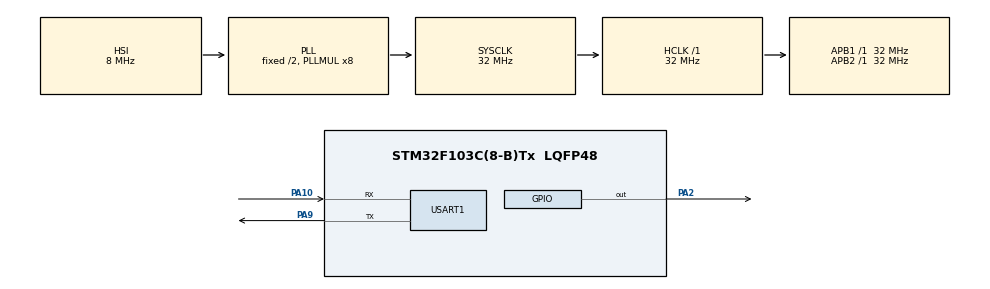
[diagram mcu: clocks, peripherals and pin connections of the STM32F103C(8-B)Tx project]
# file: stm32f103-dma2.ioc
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Dma.Request0=TIM2_UP
Dma.TIM2_UP.0.Direction=DMA_MEMORY_TO_PERIPH
Dma.TIM2_UP.0.Instance=DMA1_Channel2
Dma.TIM2_UP.0.MemDataAlignment=DMA_MDATAALIGN_WORD
Dma.TIM2_UP.0.MemInc=DMA_MINC_ENABLE
Dma.TIM2_UP.0.Mode=DMA_NORMAL
Dma.TIM2_UP.0.PeriphDataAlignment=DMA_PDATAALIGN_WORD
Dma.TIM2_UP.0.PeriphInc=DMA_PINC_DISABLE
Dma.TIM2_UP.0.Priority=DMA_PRIORITY_VERY_HIGH
Mcu.Family=STM32F1
Mcu.Name=STM32F103C(8-B)Tx
Mcu.Package=LQFP48
NVIC.DMA1_Channel2_IRQn=true\:0\:0\:false\:false\:true\:false\:true\:true
NVIC.PriorityGroup=NVIC_PRIORITYGROUP_4
PA10.Mode=Asynchronous
PA10.Signal=USART1_RX
PA2.GPIO_Speed=GPIO_SPEED_FREQ_HIGH
PA2.PinState=GPIO_PIN_SET
PA2.Signal=GPIO_Output
PA9.Mode=Asynchronous
PA9.Signal=USART1_TX
ProjectManager.HeapSize=0x200
ProjectManager.StackSize=0x400
ProjectManager.TargetToolchain=EWARM V8.32
RCC.AHBFreq_Value=32000000
RCC.APB1Freq_Value=32000000
RCC.APB1TimFreq_Value=32000000
RCC.APB2Freq_Value=32000000
RCC.APB2TimFreq_Value=32000000
RCC.HCLKFreq_Value=32000000
RCC.PLLMUL=RCC_PLL_MUL8
RCC.SYSCLKFreq_VALUE=32000000
RCC.SYSCLKSource=RCC_SYSCLKSOURCE_PLLCLK
RCC.USBFreq_Value=32000000
USART1.VirtualMode=VM_ASYNC
VP_SYS_VS_ND.Mode=No_Debug
VP_TIM2_VS_ClockSourceINT.Mode=Internal
board=custom

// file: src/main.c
/* USER CODE BEGIN Header */
/**
 ******************************************************************************
 * @file           : main.c
 * @brief          : Main program body
 ******************************************************************************
 * @attention
 *
 * Copyright (c) 2023 STMicroelectronics.
 * All rights reserved.
 *
 * This software is licensed under terms that can be found in the LICENSE file
 * in the root directory of this software component.
 * If no LICENSE file comes with this software, it is provided AS-IS.
 *
 ******************************************************************************
 */
/* USER CODE END Header */
#include "main.h"

/* USER CODE BEGIN Includes */
#include "stdio.h"

/* USER CODE END Includes */

TIM_HandleTypeDef htim2;
DMA_HandleTypeDef hdma_tim2_up;

UART_HandleTypeDef huart1;

void SystemClock_Config(void);
static void MX_DMA_Init(void);
static void MX_GPIO_Init(void);
static void MX_TIM2_Init(void);
static void MX_USART1_UART_Init(void);

/* USER CODE BEGIN 0 */
int _write(int file, char *ptr, int len)
{
    HAL_UART_Transmit(&huart1, (uint8_t *)ptr, len, 10);
    return len;
}

/* USER CODE END 0 */

int main(void)
{

    /* MCU Configuration--------------------------------------------------------*/

    /* Reset of all peripherals, Initializes the Flash interface and the Systick. */
    HAL_Init();

    /* Configure the system clock */
    SystemClock_Config();

    /* Initialize all configured peripherals */
    MX_DMA_Init();
    MX_GPIO_Init();
    MX_TIM2_Init();
    MX_USART1_UART_Init();
    /* USER CODE BEGIN 2 */

    HAL_GPIO_WritePin(GPIOA, GPIO_PIN_2, GPIO_PIN_RESET);

#define LED_NUM 6
#define BUFFER_SIZE 8 * 3 * 3 * LED_NUM + 1
#define DATA_SIZE LED_NUM * 3

    setbuf(stdout, NULL);

    uint8_t data[DATA_SIZE];
    uint32_t dma_buf[BUFFER_SIZE + 1];

    __HAL_DMA_ENABLE(&hdma_tim2_up);
    __HAL_TIM_ENABLE_DMA(&htim2, TIM_DMA_UPDATE);

    printf("init done\n");

    /* USER CODE END 2 */

    /* Infinite loop */
    /* USER CODE BEGIN WHILE */
    int n = 0;
    HAL_Delay(1000);
    while (1)
    {
        /* USER CODE END WHILE */
        printf("n: %d\n", n);
        HAL_GPIO_WritePin(GPIOA, GPIO_PIN_2, GPIO_PIN_RESET);

        /* USER CODE BEGIN 3 */

        for (int i = 0; i < LED_NUM; i++)
        {
            switch ((n + i) % 6)
            {
            case 0:
                data[i * 3] = 0x20;
                data[i * 3 + 1] = 0x00;
                data[i * 3 + 2] = 0x00;
                break;
            case 1:
                data[i * 3] = 0x20;
                data[i * 3 + 1] = 0x20;
                data[i * 3 + 2] = 0x00;
                break;
            case 2:
                data[i * 3] = 0x00;
                data[i * 3 + 1] = 0x20;
                data[i * 3 + 2] = 0x00;
                break;
            case 3:
                data[i * 3] = 0x00;
                data[i * 3 + 1] = 0x20;
                data[i * 3 + 2] = 0x20;
                break;
            case 4:
                data[i * 3] = 0x00;
                data[i * 3 + 1] = 0x00;
                data[i * 3 + 2] = 0x20;
                break;
            case 5:
                data[i * 3] = 0x20;
                data[i * 3 + 1] = 0x00;
                data[i * 3 + 2] = 0x20;
                break;
            }
        }

        HAL_TIM_Base_Stop(&htim2);
        dma_buf[0] = GPIO_PIN_2 << 16; // L;
        int m = 1;
        for (int i = 0; i < DATA_SIZE; i++)
        {
            uint16_t c = data[i];
            for (int j = 0; j < 8; j++)
            {
                if (c & 0x1)
                {

                    dma_buf[m++] = GPIO_PIN_2;       // H
                    dma_buf[m++] = GPIO_PIN_2;       // H
                    dma_buf[m++] = GPIO_PIN_2 << 16; // L
                }
                else
                {
                    dma_buf[m++] = GPIO_PIN_2;       // H
                    dma_buf[m++] = GPIO_PIN_2 << 16; // L
                    dma_buf[m++] = GPIO_PIN_2 << 16; // L
                }
                c = c >> 1;
            }
        }
        n++;
        // Tim2 のカウンタをリセット
        __HAL_TIM_SET_COUNTER(&htim2, 0);
        HAL_DMA_Start_IT(&hdma_tim2_up, (uint32_t)dma_buf, (uint32_t)&GPIOA->BSRR, BUFFER_SIZE);
        HAL_TIM_Base_Start(&htim2);

        HAL_Delay(500);
        /* USER CODE END WHILE */

        /* USER CODE BEGIN 3 */
    }
    /* USER CODE END 3 */
}

void SystemClock_Config(void)
{
    RCC_OscInitTypeDef RCC_OscInitStruct = {0};
    RCC_ClkInitTypeDef RCC_ClkInitStruct = {0};

    /** Initializes the RCC Oscillators according to the specified parameters
     * in the RCC_OscInitTypeDef structure.
     */
    RCC_OscInitStruct.OscillatorType = RCC_OSCILLATORTYPE_HSI;
    RCC_OscInitStruct.HSIState = RCC_HSI_ON;
    RCC_OscInitStruct.HSICalibrationValue = RCC_HSICALIBRATION_DEFAULT;
    RCC_OscInitStruct.PLL.PLLState = RCC_PLL_ON;
    RCC_OscInitStruct.PLL.PLLSource = RCC_PLLSOURCE_HSI_DIV2;
    RCC_OscInitStruct.PLL.PLLMUL = RCC_PLL_MUL8;
    if (HAL_RCC_OscConfig(&RCC_OscInitStruct) != HAL_OK)
    {
        Error_Handler();
    }

    /** Initializes the CPU, AHB and APB buses clocks
     */
    RCC_ClkInitStruct.ClockType = RCC_CLOCKTYPE_HCLK | RCC_CLOCKTYPE_SYSCLK | RCC_CLOCKTYPE_PCLK1 | RCC_CLOCKTYPE_PCLK2;
    RCC_ClkInitStruct.SYSCLKSource = RCC_SYSCLKSOURCE_PLLCLK;
    RCC_ClkInitStruct.AHBCLKDivider = RCC_SYSCLK_DIV1;
    RCC_ClkInitStruct.APB1CLKDivider = RCC_HCLK_DIV1;
    RCC_ClkInitStruct.APB2CLKDivider = RCC_HCLK_DIV1;

    if (HAL_RCC_ClockConfig(&RCC_ClkInitStruct, FLASH_LATENCY_1) != HAL_OK)
    {
        Error_Handler();
    }
}

static void MX_TIM2_Init(void)
{

    TIM_ClockConfigTypeDef sClockSourceConfig = {0};
    TIM_MasterConfigTypeDef sMasterConfig = {0};

    htim2.Instance = TIM2;
    htim2.Init.Prescaler = 0;
    htim2.Init.CounterMode = TIM_COUNTERMODE_UP;
    htim2.Init.Period = SystemCoreClock / 2500000;
    htim2.Init.ClockDivision = TIM_CLOCKDIVISION_DIV1;
    htim2.Init.AutoReloadPreload = TIM_AUTORELOAD_PRELOAD_DISABLE;
    if (HAL_TIM_Base_Init(&htim2) != HAL_OK)
    {
        Error_Handler();
    }
    sClockSourceConfig.ClockSource = TIM_CLOCKSOURCE_INTERNAL;
    if (HAL_TIM_ConfigClockSource(&htim2, &sClockSourceConfig) != HAL_OK)
    {
        Error_Handler();
    }
    sMasterConfig.MasterOutputTrigger = TIM_TRGO_RESET;
    sMasterConfig.MasterSlaveMode = TIM_MASTERSLAVEMODE_DISABLE;
    if (HAL_TIMEx_MasterConfigSynchronization(&htim2, &sMasterConfig) != HAL_OK)
    {
        Error_Handler();
    }
}

static void MX_USART1_UART_Init(void)
{

    huart1.Instance = USART1;
    huart1.Init.BaudRate = 115200;
    huart1.Init.WordLength = UART_WORDLENGTH_8B;
    huart1.Init.StopBits = UART_STOPBITS_1;
    huart1.Init.Parity = UART_PARITY_NONE;
    huart1.Init.Mode = UART_MODE_TX_RX;
    huart1.Init.HwFlowCtl = UART_HWCONTROL_NONE;
    huart1.Init.OverSampling = UART_OVERSAMPLING_16;
    if (HAL_UART_Init(&huart1) != HAL_OK)
    {
        Error_Handler();
    }
}

static void MX_DMA_Init(void)
{

    /* DMA controller clock enable */
    __HAL_RCC_DMA1_CLK_ENABLE();

    /* DMA interrupt init */
    /* DMA1_Channel2_IRQn interrupt configuration */
    HAL_NVIC_SetPriority(DMA1_Channel2_IRQn, 0, 0);
    HAL_NVIC_EnableIRQ(DMA1_Channel2_IRQn);
}

static void MX_GPIO_Init(void)
{
    GPIO_InitTypeDef GPIO_InitStruct = {0};

    /* GPIO Ports Clock Enable */
    __HAL_RCC_GPIOA_CLK_ENABLE();

    /*Configure GPIO pin Output Level */
    HAL_GPIO_WritePin(GPIOA, GPIO_PIN_2, GPIO_PIN_SET);

    /*Configure GPIO pin : PA2 */
    GPIO_InitStruct.Pin = GPIO_PIN_2;
    GPIO_InitStruct.Mode = GPIO_MODE_OUTPUT_PP;
    GPIO_InitStruct.Pull = GPIO_NOPULL;
    GPIO_InitStruct.Speed = GPIO_SPEED_FREQ_HIGH;
    HAL_GPIO_Init(GPIOA, &GPIO_InitStruct);

}

void Error_Handler(void)
{
    __disable_irq();
    while (1)
    {
    }
}
